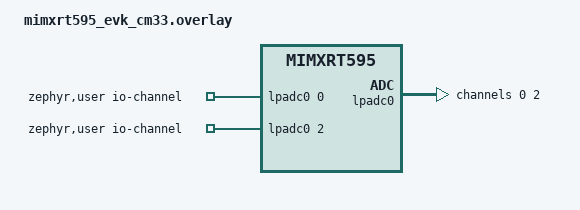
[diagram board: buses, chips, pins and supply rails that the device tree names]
/*
 * SPDX-License-Identifier: Apache-2.0
 *
 * Copyright (c) 2020 Linaro Limited
 */

#include <zephyr/dt-bindings/adc/adc.h>

/ {
	zephyr,user {
		/* adjust channel number according to pinmux in board.dts */
		io-channels = <&lpadc0 0>, <&lpadc0 2>;
	};
};

&lpadc0 {
	#address-cells = <1>;
	#size-cells = <0>;

	/*
	 * To use this sample:
	 * - Connect LPADC0 CH0 signal to voltage between 0~1.8V (J30 pin 1)
	 * - Connect LPADC0 CH2 signal to voltage between 0~1.8V (J30 pin 3)
	 */

	channel@0 {
		reg = <0>;
		zephyr,gain = "ADC_GAIN_1";
		zephyr,reference = "ADC_REF_EXTERNAL0";
		zephyr,vref-mv = <1800>;
		zephyr,acquisition-time = <ADC_ACQ_TIME_DEFAULT>;
		zephyr,resolution = <12>;
	};

	channel@2 {
		reg = <2>;
		zephyr,gain = "ADC_GAIN_1";
		zephyr,reference = "ADC_REF_EXTERNAL0";
		zephyr,vref-mv = <1800>;
		zephyr,acquisition-time = <ADC_ACQ_TIME_DEFAULT>;
		zephyr,resolution = <12>;
	};
};
